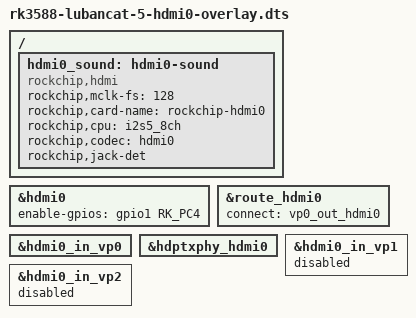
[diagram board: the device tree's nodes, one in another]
/dts-v1/;
/plugin/;

#include <dt-bindings/gpio/gpio.h>
#include <dt-bindings/pinctrl/rockchip.h>
#include <dt-bindings/display/drm_mipi_dsi.h>
#include <dt-bindings/interrupt-controller/irq.h>

/ {
	fragment@0 {
		target = <&hdmi0>;

		__overlay__ {
			enable-gpios = <&gpio1 RK_PC4 GPIO_ACTIVE_HIGH>;
			status = "okay";
		};
	};

	fragment@1 {
		target = <&route_hdmi0>;

		__overlay__ {
			status = "okay";
			connect = <&vp0_out_hdmi0>;
		};
	};

	fragment@2 {
		target = <&hdmi0_in_vp0>;

		__overlay__ {
			status = "okay";
		};
	};

	fragment@3 {
		target = <&hdptxphy_hdmi0>;

		__overlay__ {
			status = "okay";
		};
	};

	fragment@4 {
		target = <&hdmi0_in_vp1>;

		__overlay__ {
			status = "disabled";
		};
	};

	fragment@5 {
		target = <&hdmi0_in_vp2>;

		__overlay__ {
			status = "disabled";
		};
	};

	fragment@6 {
		target-path = "/";

		__overlay__ {
			hdmi0_sound: hdmi0-sound {
				status = "okay";
				compatible = "rockchip,hdmi";
				rockchip,mclk-fs = <128>;
				rockchip,card-name = "rockchip-hdmi0";
				rockchip,cpu = <&i2s5_8ch>;
				rockchip,codec = <&hdmi0>;
				rockchip,jack-det;
			};
		};
	};
};

